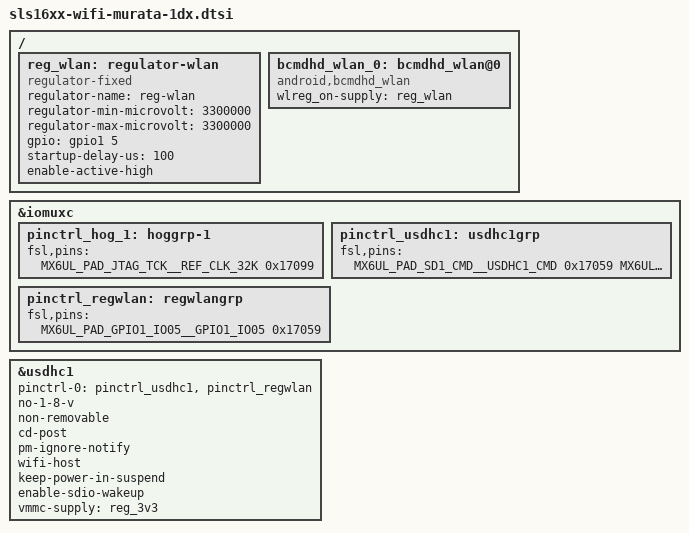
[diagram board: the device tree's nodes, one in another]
/*
 * This program is free software; you can redistribute it and/or modify
 * it under the terms of the GNU General Public License version 2 as
 * published by the Free Software Foundation.
 */

/ {
	/* Wi-Fi regulator */
	reg_wlan: regulator-wlan {
		compatible = "regulator-fixed";
		regulator-name = "reg-wlan";
		regulator-min-microvolt = <3300000>;
		regulator-max-microvolt = <3300000>;
		gpio = <&gpio1 5 0>;
		startup-delay-us = <100>;
		enable-active-high;
	};

	/* Wi-Fi driver */
	bcmdhd_wlan_0: bcmdhd_wlan@0 {
		compatible = "android,bcmdhd_wlan";
		wlreg_on-supply = <&reg_wlan>;
	};
};

/* IO multiplexing */
&iomuxc {
	/* Wi-Fi 32kHz low power clock reference */
	pinctrl_hog_1: hoggrp-1 {
		fsl,pins = <
			MX6UL_PAD_JTAG_TCK__REF_CLK_32K 0x17099
		>;
	};

	/* Wi-Fi */
	pinctrl_usdhc1: usdhc1grp {
		fsl,pins = <
			MX6UL_PAD_SD1_CMD__USDHC1_CMD     0x17059
			MX6UL_PAD_SD1_CLK__USDHC1_CLK     0x10071
			MX6UL_PAD_SD1_DATA0__USDHC1_DATA0 0x17059
			MX6UL_PAD_SD1_DATA1__USDHC1_DATA1 0x17059
			MX6UL_PAD_SD1_DATA2__USDHC1_DATA2 0x17059
			MX6UL_PAD_SD1_DATA3__USDHC1_DATA3 0x17059
		>;
	};

	/* Wi-Fi regulator enable */
	pinctrl_regwlan: regwlangrp {
		fsl,pins = <
			MX6UL_PAD_GPIO1_IO05__GPIO1_IO05 0x17059
		>;
	};
};

/* Wi-Fi */
&usdhc1 {
	pinctrl-names = "default";
	pinctrl-0 = <&pinctrl_usdhc1 &pinctrl_regwlan>;
	no-1-8-v;
	non-removable;
	cd-post;
	pm-ignore-notify;
	wifi-host;
	keep-power-in-suspend;
	enable-sdio-wakeup;
	vmmc-supply = <&reg_3v3>;
	status = "okay";
};
